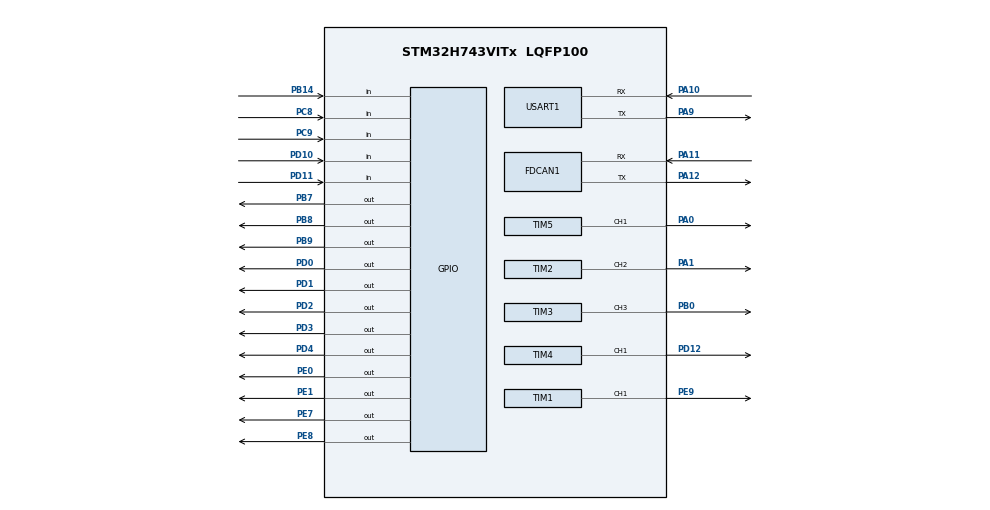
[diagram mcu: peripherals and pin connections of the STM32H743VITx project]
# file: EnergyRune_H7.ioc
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CORTEX_M7.AccessPermission_S-Cortex_Memory_Protection_Unit_Region1_Settings_S=MPU_REGION_FULL_ACCESS
CORTEX_M7.BaseAddress_S-Cortex_Memory_Protection_Unit_Region1_Settings_S=0x30000000
CORTEX_M7.CPU_ICache=Enabled
CORTEX_M7.Enable_S-Cortex_Memory_Protection_Unit_Region1_Settings_S=MPU_REGION_ENABLE
CORTEX_M7.IsBufferable_S-Cortex_Memory_Protection_Unit_Region1_Settings_S=MPU_ACCESS_BUFFERABLE
CORTEX_M7.IsShareable_S-Cortex_Memory_Protection_Unit_Region1_Settings_S=MPU_ACCESS_SHAREABLE
CORTEX_M7.Size_S-Cortex_Memory_Protection_Unit_Region1_Settings_S=MPU_REGION_SIZE_256KB
CORTEX_M7.TypeExtField_S-Cortex_Memory_Protection_Unit_Region1_Settings_S=MPU_TEX_LEVEL1
CORTEX_M7.default_mode_Activation=1
Dma.Request0=TIM4_CH1
Dma.Request1=TIM3_CH3
Dma.TIM3_CH3.1.Direction=DMA_MEMORY_TO_PERIPH
Dma.TIM3_CH3.1.EventEnable=DISABLE
Dma.TIM3_CH3.1.FIFOMode=DMA_FIFOMODE_DISABLE
Dma.TIM3_CH3.1.Instance=DMA1_Stream3
Dma.TIM3_CH3.1.MemDataAlignment=DMA_MDATAALIGN_HALFWORD
Dma.TIM3_CH3.1.MemInc=DMA_MINC_ENABLE
Dma.TIM3_CH3.1.Mode=DMA_NORMAL
Dma.TIM3_CH3.1.PeriphDataAlignment=DMA_PDATAALIGN_HALFWORD
Dma.TIM3_CH3.1.PeriphInc=DMA_PINC_DISABLE
Dma.TIM3_CH3.1.Polarity=HAL_DMAMUX_REQ_GEN_RISING
Dma.TIM3_CH3.1.Priority=DMA_PRIORITY_HIGH
Dma.TIM3_CH3.1.RequestNumber=1
Dma.TIM3_CH3.1.SignalID=NONE
Dma.TIM3_CH3.1.SyncEnable=DISABLE
Dma.TIM3_CH3.1.SyncPolarity=HAL_DMAMUX_SYNC_NO_EVENT
Dma.TIM3_CH3.1.SyncRequestNumber=1
Dma.TIM3_CH3.1.SyncSignalID=NONE
Dma.TIM4_CH1.0.Direction=DMA_MEMORY_TO_PERIPH
Dma.TIM4_CH1.0.EventEnable=DISABLE
Dma.TIM4_CH1.0.FIFOMode=DMA_FIFOMODE_DISABLE
Dma.TIM4_CH1.0.Instance=DMA1_Stream0
Dma.TIM4_CH1.0.MemDataAlignment=DMA_MDATAALIGN_HALFWORD
Dma.TIM4_CH1.0.MemInc=DMA_MINC_ENABLE
Dma.TIM4_CH1.0.Mode=DMA_NORMAL
Dma.TIM4_CH1.0.PeriphDataAlignment=DMA_PDATAALIGN_HALFWORD
Dma.TIM4_CH1.0.PeriphInc=DMA_PINC_DISABLE
Dma.TIM4_CH1.0.Polarity=HAL_DMAMUX_REQ_GEN_RISING
Dma.TIM4_CH1.0.Priority=DMA_PRIORITY_HIGH
Dma.TIM4_CH1.0.RequestNumber=1
Dma.TIM4_CH1.0.SignalID=NONE
Dma.TIM4_CH1.0.SyncEnable=DISABLE
Dma.TIM4_CH1.0.SyncPolarity=HAL_DMAMUX_SYNC_NO_EVENT
Dma.TIM4_CH1.0.SyncRequestNumber=1
Dma.TIM4_CH1.0.SyncSignalID=NONE
FDCAN1.CalculateBaudRateNominal=1000000
FDCAN1.CalculateTimeBitNominal=1000
FDCAN1.CalculateTimeQuantumNominal=50.0
FDCAN1.NominalPrescaler=6
FDCAN1.NominalTimeSeg1=15
FDCAN1.NominalTimeSeg2=4
FDCAN1.RxFifo0ElmtsNbr=32
FDCAN1.StdFiltersNbr=1
Mcu.Family=STM32H7
Mcu.Name=STM32H743VITx
Mcu.Package=LQFP100
NVIC.DMA1_Stream0_IRQn=true\:0\:0\:false\:false\:true\:false\:true\:true
NVIC.DMA1_Stream3_IRQn=true\:0\:0\:false\:false\:true\:false\:true\:true
NVIC.PriorityGroup=NVIC_PRIORITYGROUP_4
NVIC.TIM3_IRQn=true\:0\:0\:false\:false\:true\:true\:true\:true
NVIC.TIM4_IRQn=true\:0\:0\:false\:false\:true\:true\:true\:true
NVIC.TIM6_DAC_IRQn=true\:0\:0\:false\:false\:true\:true\:true\:true
PA0.Signal=S_TIM5_CH1
PA1.Signal=S_TIM2_CH2
PA10.Mode=Asynchronous
PA10.Signal=USART1_RX
PA11.Mode=FDCAN_Activate
PA11.Signal=FDCAN1_RX
PA12.Mode=FDCAN_Activate
PA12.Signal=FDCAN1_TX
PA13\ (JTMS/SWDIO).Mode=Serial_Wire
PA13\ (JTMS/SWDIO).Signal=DEBUG_JTMS-SWDIO
PA14\ (JTCK/SWCLK).Mode=Serial_Wire
PA14\ (JTCK/SWCLK).Signal=DEBUG_JTCK-SWCLK
PA9.Mode=Asynchronous
PA9.Signal=USART1_TX
PB0.Signal=S_TIM3_CH3
PB14.Signal=GPIO_Input
PB7.Signal=GPIO_Output
PB8.Signal=GPIO_Output
PB9.Signal=GPIO_Output
PC8.Signal=GPIO_Input
PC9.Signal=GPIO_Input
PD0.Signal=GPIO_Output
PD1.Signal=GPIO_Output
PD10.Signal=GPIO_Input
PD11.Signal=GPIO_Input
PD12.Signal=S_TIM4_CH1
PD2.Signal=GPIO_Output
PD3.Signal=GPIO_Output
PD4.Signal=GPIO_Output
PE0.Signal=GPIO_Output
PE1.Signal=GPIO_Output
PE7.Signal=GPIO_Output
PE8.Signal=GPIO_Output
PE9.Signal=S_TIM1_CH1
PH0-OSC_IN\ (PH0).Mode=HSE-External-Oscillator
PH0-OSC_IN\ (PH0).Signal=RCC_OSC_IN
PH1-OSC_OUT\ (PH1).Mode=HSE-External-Oscillator
PH1-OSC_OUT\ (PH1).Signal=RCC_OSC_OUT
ProjectManager.HeapSize=0x200
ProjectManager.StackSize=0x400
ProjectManager.TargetToolchain=MDK-ARM V5.27
RCC.ADCFreq_Value=32250000
RCC.APB1Freq_Value=120000000
RCC.APB2Freq_Value=120000000
RCC.APB3Freq_Value=120000000
RCC.APB4Freq_Value=120000000
RCC.CortexFreq_Value=480000000
RCC.D1PPRE=RCC_APB3_DIV2
RCC.D2PPRE1=RCC_APB1_DIV2
RCC.D2PPRE2=RCC_APB2_DIV2
RCC.D3PPRE=RCC_APB4_DIV2
RCC.DIVM1=1
RCC.DIVN1=60
RCC.DIVQ1=8
RCC.HCLKFreq_Value=240000000
RCC.HPRE=RCC_HCLK_DIV2
RCC.HSE_VALUE=16000000
RCC.PLLFRACN=0
RCC.PLLSourceVirtual=RCC_PLLSOURCE_HSE
RCC.SYSCLKFreq_VALUE=480000000
RCC.SYSCLKSource=RCC_SYSCLKSOURCE_PLLCLK
RCC.USBFreq_Value=120000000
SH.S_TIM1_CH1.0=TIM1_CH1,PWM Generation1 CH1
SH.S_TIM2_CH2.0=TIM2_CH2,PWM Generation2 CH2
SH.S_TIM3_CH3.0=TIM3_CH3,PWM Generation3 CH3
SH.S_TIM4_CH1.0=TIM4_CH1,PWM Generation1 CH1
SH.S_TIM5_CH1.0=TIM5_CH1,PWM Generation1 CH1
TIM1.Channel-PWM\ Generation1\ CH1=TIM_CHANNEL_1
TIM1.Period=299
TIM2.Channel-PWM\ Generation2\ CH2=TIM_CHANNEL_2
TIM2.Period=299
TIM3.Channel-PWM\ Generation3\ CH3=TIM_CHANNEL_3
TIM3.Period=299
TIM4.Channel-PWM\ Generation1\ CH1=TIM_CHANNEL_1
TIM4.CounterMode=TIM_COUNTERMODE_UP
TIM4.Period=299
TIM5.Channel-PWM\ Generation1\ CH1=TIM_CHANNEL_1
TIM5.Period=299
TIM6.Period=9999
TIM6.Prescaler=24
USART1.VirtualMode-Asynchronous=VM_ASYNC
VP_MEMORYMAP_VS_MEMORYMAP.Mode=CurAppReg
VP_RNG_VS_RNG.Mode=RNG_Activate
VP_TIM3_VS_ClockSourceINT.Mode=Internal
VP_TIM4_VS_ClockSourceINT.Mode=Internal
VP_TIM6_VS_ClockSourceINT.Mode=Enable_Timer
board=custom

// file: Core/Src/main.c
/* USER CODE BEGIN Header */
/**
  ******************************************************************************
  * @file           : main.c
  * @brief          : Main program body
  ******************************************************************************
  * @attention
  *
  * Copyright (c) 2026 STMicroelectronics.
  * All rights reserved.
  *
  * This software is licensed under terms that can be found in the LICENSE file
  * in the root directory of this software component.
  * If no LICENSE file comes with this software, it is provided AS-IS.
  *
  ******************************************************************************
  */
/* USER CODE END Header */
#include "main.h"

#include "cmd_parser.h"
#include "software_config.h"

FDCAN_HandleTypeDef hfdcan1;

RNG_HandleTypeDef hrng;

TIM_HandleTypeDef htim1;
TIM_HandleTypeDef htim2;
TIM_HandleTypeDef htim3;
TIM_HandleTypeDef htim4;
TIM_HandleTypeDef htim5;
TIM_HandleTypeDef htim6;
DMA_HandleTypeDef hdma_tim3_ch3;
DMA_HandleTypeDef hdma_tim4_ch1;

UART_HandleTypeDef huart1;

/* USER CODE BEGIN PV */
int rune_mode  = BIG_RUNE;
gError_t gError=
    {
    0,0,0
};
extern int flag_data_process;
/* USER CODE END PV */

void SystemClock_Config(void);
static void MPU_Config(void);
static void MX_GPIO_Init(void);
static void MX_DMA_Init(void);
static void MX_FDCAN1_Init(void);
static void MX_TIM3_Init(void);
static void MX_TIM4_Init(void);
static void MX_TIM6_Init(void);
static void MX_USART1_UART_Init(void);
static void MX_RNG_Init(void);
static void MX_TIM1_Init(void);
static void MX_TIM2_Init(void);
static void MX_TIM5_Init(void);

int main(void)
{

  /* USER CODE BEGIN 1 */
int ok=0;
  /* USER CODE END 1 */

  /* MPU Configuration--------------------------------------------------------*/
  MPU_Config();

  /* Enable the CPU Cache */

  /* Enable I-Cache---------------------------------------------------------*/
  SCB_EnableICache();

  /* MCU Configuration--------------------------------------------------------*/

  /* Reset of all peripherals, Initializes the Flash interface and the Systick. */
  HAL_Init();

  /* Configure the system clock */
  SystemClock_Config();

  /* Initialize all configured peripherals */
  MX_GPIO_Init();
  MX_DMA_Init();
  MX_FDCAN1_Init();
  MX_TIM3_Init();
  MX_TIM4_Init();
  MX_TIM6_Init();
  MX_USART1_UART_Init();
  MX_RNG_Init();
  MX_TIM1_Init();
  MX_TIM2_Init();
  MX_TIM5_Init();
  /* USER CODE BEGIN 2 */
    HAL_TIM_Base_Start_IT(&htim6);
  /* USER CODE END 2 */

  /* Infinite loop */
  while (1)
  {
    /* USER CODE BEGIN 3 */
if (flag_data_process=1)
    CmdParser_HandleUartData();
  }
  /* USER CODE END 3 */
}

void SystemClock_Config(void)
{
  RCC_OscInitTypeDef RCC_OscInitStruct = {0};
  RCC_ClkInitTypeDef RCC_ClkInitStruct = {0};

  /** Supply configuration update enable
  */
  HAL_PWREx_ConfigSupply(PWR_LDO_SUPPLY);

  /** Configure the main internal regulator output voltage
  */
  __HAL_PWR_VOLTAGESCALING_CONFIG(PWR_REGULATOR_VOLTAGE_SCALE0);

  while(!__HAL_PWR_GET_FLAG(PWR_FLAG_VOSRDY)) {}

  /** Initializes the RCC Oscillators according to the specified parameters
  * in the RCC_OscInitTypeDef structure.
  */
  RCC_OscInitStruct.OscillatorType = RCC_OSCILLATORTYPE_HSI48|RCC_OSCILLATORTYPE_HSE;
  RCC_OscInitStruct.HSEState = RCC_HSE_ON;
  RCC_OscInitStruct.HSI48State = RCC_HSI48_ON;
  RCC_OscInitStruct.PLL.PLLState = RCC_PLL_ON;
  RCC_OscInitStruct.PLL.PLLSource = RCC_PLLSOURCE_HSE;
  RCC_OscInitStruct.PLL.PLLM = 1;
  RCC_OscInitStruct.PLL.PLLN = 60;
  RCC_OscInitStruct.PLL.PLLP = 2;
  RCC_OscInitStruct.PLL.PLLQ = 8;
  RCC_OscInitStruct.PLL.PLLR = 2;
  RCC_OscInitStruct.PLL.PLLRGE = RCC_PLL1VCIRANGE_3;
  RCC_OscInitStruct.PLL.PLLVCOSEL = RCC_PLL1VCOWIDE;
  RCC_OscInitStruct.PLL.PLLFRACN = 0;
  if (HAL_RCC_OscConfig(&RCC_OscInitStruct) != HAL_OK)
  {
    Error_Handler();
  }

  /** Initializes the CPU, AHB and APB buses clocks
  */
  RCC_ClkInitStruct.ClockType = RCC_CLOCKTYPE_HCLK|RCC_CLOCKTYPE_SYSCLK
                              |RCC_CLOCKTYPE_PCLK1|RCC_CLOCKTYPE_PCLK2
                              |RCC_CLOCKTYPE_D3PCLK1|RCC_CLOCKTYPE_D1PCLK1;
  RCC_ClkInitStruct.SYSCLKSource = RCC_SYSCLKSOURCE_PLLCLK;
  RCC_ClkInitStruct.SYSCLKDivider = RCC_SYSCLK_DIV1;
  RCC_ClkInitStruct.AHBCLKDivider = RCC_HCLK_DIV2;
  RCC_ClkInitStruct.APB3CLKDivider = RCC_APB3_DIV2;
  RCC_ClkInitStruct.APB1CLKDivider = RCC_APB1_DIV2;
  RCC_ClkInitStruct.APB2CLKDivider = RCC_APB2_DIV2;
  RCC_ClkInitStruct.APB4CLKDivider = RCC_APB4_DIV2;

  if (HAL_RCC_ClockConfig(&RCC_ClkInitStruct, FLASH_LATENCY_4) != HAL_OK)
  {
    Error_Handler();
  }
}

static void MX_FDCAN1_Init(void)
{

  hfdcan1.Instance = FDCAN1;
  hfdcan1.Init.FrameFormat = FDCAN_FRAME_CLASSIC;
  hfdcan1.Init.Mode = FDCAN_MODE_NORMAL;
  hfdcan1.Init.AutoRetransmission = DISABLE;
  hfdcan1.Init.TransmitPause = DISABLE;
  hfdcan1.Init.ProtocolException = DISABLE;
  hfdcan1.Init.NominalPrescaler = 6;
  hfdcan1.Init.NominalSyncJumpWidth = 1;
  hfdcan1.Init.NominalTimeSeg1 = 15;
  hfdcan1.Init.NominalTimeSeg2 = 4;
  hfdcan1.Init.DataPrescaler = 1;
  hfdcan1.Init.DataSyncJumpWidth = 1;
  hfdcan1.Init.DataTimeSeg1 = 1;
  hfdcan1.Init.DataTimeSeg2 = 1;
  hfdcan1.Init.MessageRAMOffset = 0;
  hfdcan1.Init.StdFiltersNbr = 1;
  hfdcan1.Init.ExtFiltersNbr = 0;
  hfdcan1.Init.RxFifo0ElmtsNbr = 32;
  hfdcan1.Init.RxFifo0ElmtSize = FDCAN_DATA_BYTES_8;
  hfdcan1.Init.RxFifo1ElmtsNbr = 0;
  hfdcan1.Init.RxFifo1ElmtSize = FDCAN_DATA_BYTES_8;
  hfdcan1.Init.RxBuffersNbr = 0;
  hfdcan1.Init.RxBufferSize = FDCAN_DATA_BYTES_8;
  hfdcan1.Init.TxEventsNbr = 0;
  hfdcan1.Init.TxBuffersNbr = 0;
  hfdcan1.Init.TxFifoQueueElmtsNbr = 0;
  hfdcan1.Init.TxFifoQueueMode = FDCAN_TX_FIFO_OPERATION;
  hfdcan1.Init.TxElmtSize = FDCAN_DATA_BYTES_8;
  if (HAL_FDCAN_Init(&hfdcan1) != HAL_OK)
  {
    Error_Handler();
  }

}

static void MX_RNG_Init(void)
{

  hrng.Instance = RNG;
  hrng.Init.ClockErrorDetection = RNG_CED_ENABLE;
  if (HAL_RNG_Init(&hrng) != HAL_OK)
  {
    Error_Handler();
  }

}

static void MX_TIM1_Init(void)
{

  TIM_MasterConfigTypeDef sMasterConfig = {0};
  TIM_OC_InitTypeDef sConfigOC = {0};
  TIM_BreakDeadTimeConfigTypeDef sBreakDeadTimeConfig = {0};

  htim1.Instance = TIM1;
  htim1.Init.Prescaler = 0;
  htim1.Init.CounterMode = TIM_COUNTERMODE_UP;
  htim1.Init.Period = 299;
  htim1.Init.ClockDivision = TIM_CLOCKDIVISION_DIV1;
  htim1.Init.RepetitionCounter = 0;
  htim1.Init.AutoReloadPreload = TIM_AUTORELOAD_PRELOAD_DISABLE;
  if (HAL_TIM_PWM_Init(&htim1) != HAL_OK)
  {
    Error_Handler();
  }
  sMasterConfig.MasterOutputTrigger = TIM_TRGO_RESET;
  sMasterConfig.MasterOutputTrigger2 = TIM_TRGO2_RESET;
  sMasterConfig.MasterSlaveMode = TIM_MASTERSLAVEMODE_DISABLE;
  if (HAL_TIMEx_MasterConfigSynchronization(&htim1, &sMasterConfig) != HAL_OK)
  {
    Error_Handler();
  }
  sConfigOC.OCMode = TIM_OCMODE_PWM1;
  sConfigOC.Pulse = 0;
  sConfigOC.OCPolarity = TIM_OCPOLARITY_HIGH;
  sConfigOC.OCNPolarity = TIM_OCNPOLARITY_HIGH;
  sConfigOC.OCFastMode = TIM_OCFAST_DISABLE;
  sConfigOC.OCIdleState = TIM_OCIDLESTATE_RESET;
  sConfigOC.OCNIdleState = TIM_OCNIDLESTATE_RESET;
  if (HAL_TIM_PWM_ConfigChannel(&htim1, &sConfigOC, TIM_CHANNEL_1) != HAL_OK)
  {
    Error_Handler();
  }
  sBreakDeadTimeConfig.OffStateRunMode = TIM_OSSR_DISABLE;
  sBreakDeadTimeConfig.OffStateIDLEMode = TIM_OSSI_DISABLE;
  sBreakDeadTimeConfig.LockLevel = TIM_LOCKLEVEL_OFF;
  sBreakDeadTimeConfig.DeadTime = 0;
  sBreakDeadTimeConfig.BreakState = TIM_BREAK_DISABLE;
  sBreakDeadTimeConfig.BreakPolarity = TIM_BREAKPOLARITY_HIGH;
  sBreakDeadTimeConfig.BreakFilter = 0;
  sBreakDeadTimeConfig.Break2State = TIM_BREAK2_DISABLE;
  sBreakDeadTimeConfig.Break2Polarity = TIM_BREAK2POLARITY_HIGH;
  sBreakDeadTimeConfig.Break2Filter = 0;
  sBreakDeadTimeConfig.AutomaticOutput = TIM_AUTOMATICOUTPUT_DISABLE;
  if (HAL_TIMEx_ConfigBreakDeadTime(&htim1, &sBreakDeadTimeConfig) != HAL_OK)
  {
    Error_Handler();
  }
  HAL_TIM_MspPostInit(&htim1);

}

static void MX_TIM2_Init(void)
{

  TIM_MasterConfigTypeDef sMasterConfig = {0};
  TIM_OC_InitTypeDef sConfigOC = {0};

  htim2.Instance = TIM2;
  htim2.Init.Prescaler = 0;
  htim2.Init.CounterMode = TIM_COUNTERMODE_UP;
  htim2.Init.Period = 299;
  htim2.Init.ClockDivision = TIM_CLOCKDIVISION_DIV1;
  htim2.Init.AutoReloadPreload = TIM_AUTORELOAD_PRELOAD_DISABLE;
  if (HAL_TIM_PWM_Init(&htim2) != HAL_OK)
  {
    Error_Handler();
  }
  sMasterConfig.MasterOutputTrigger = TIM_TRGO_RESET;
  sMasterConfig.MasterSlaveMode = TIM_MASTERSLAVEMODE_DISABLE;
  if (HAL_TIMEx_MasterConfigSynchronization(&htim2, &sMasterConfig) != HAL_OK)
  {
    Error_Handler();
  }
  sConfigOC.OCMode = TIM_OCMODE_PWM1;
  sConfigOC.Pulse = 0;
  sConfigOC.OCPolarity = TIM_OCPOLARITY_HIGH;
  sConfigOC.OCFastMode = TIM_OCFAST_DISABLE;
  if (HAL_TIM_PWM_ConfigChannel(&htim2, &sConfigOC, TIM_CHANNEL_2) != HAL_OK)
  {
    Error_Handler();
  }
  HAL_TIM_MspPostInit(&htim2);

}

static void MX_TIM3_Init(void)
{

  TIM_ClockConfigTypeDef sClockSourceConfig = {0};
  TIM_MasterConfigTypeDef sMasterConfig = {0};
  TIM_OC_InitTypeDef sConfigOC = {0};

  htim3.Instance = TIM3;
  htim3.Init.Prescaler = 0;
  htim3.Init.CounterMode = TIM_COUNTERMODE_UP;
  htim3.Init.Period = 299;
  htim3.Init.ClockDivision = TIM_CLOCKDIVISION_DIV1;
  htim3.Init.AutoReloadPreload = TIM_AUTORELOAD_PRELOAD_DISABLE;
  if (HAL_TIM_Base_Init(&htim3) != HAL_OK)
  {
    Error_Handler();
  }
  sClockSourceConfig.ClockSource = TIM_CLOCKSOURCE_INTERNAL;
  if (HAL_TIM_ConfigClockSource(&htim3, &sClockSourceConfig) != HAL_OK)
  {
    Error_Handler();
  }
  if (HAL_TIM_PWM_Init(&htim3) != HAL_OK)
  {
    Error_Handler();
  }
  sMasterConfig.MasterOutputTrigger = TIM_TRGO_RESET;
  sMasterConfig.MasterSlaveMode = TIM_MASTERSLAVEMODE_DISABLE;
  if (HAL_TIMEx_MasterConfigSynchronization(&htim3, &sMasterConfig) != HAL_OK)
  {
    Error_Handler();
  }
  sConfigOC.OCMode = TIM_OCMODE_PWM1;
  sConfigOC.Pulse = 0;
  sConfigOC.OCPolarity = TIM_OCPOLARITY_HIGH;
  sConfigOC.OCFastMode = TIM_OCFAST_DISABLE;
  if (HAL_TIM_PWM_ConfigChannel(&htim3, &sConfigOC, TIM_CHANNEL_3) != HAL_OK)
  {
    Error_Handler();
  }
  HAL_TIM_MspPostInit(&htim3);

}

static void MX_TIM4_Init(void)
{

  TIM_ClockConfigTypeDef sClockSourceConfig = {0};
  TIM_MasterConfigTypeDef sMasterConfig = {0};
  TIM_OC_InitTypeDef sConfigOC = {0};

  htim4.Instance = TIM4;
  htim4.Init.Prescaler = 0;
  htim4.Init.CounterMode = TIM_COUNTERMODE_UP;
  htim4.Init.Period = 299;
  htim4.Init.ClockDivision = TIM_CLOCKDIVISION_DIV1;
  htim4.Init.AutoReloadPreload = TIM_AUTORELOAD_PRELOAD_DISABLE;
  if (HAL_TIM_Base_Init(&htim4) != HAL_OK)
  {
    Error_Handler();
  }
  sClockSourceConfig.ClockSource = TIM_CLOCKSOURCE_INTERNAL;
  if (HAL_TIM_ConfigClockSource(&htim4, &sClockSourceConfig) != HAL_OK)
  {
    Error_Handler();
  }
  if (HAL_TIM_PWM_Init(&htim4) != HAL_OK)
  {
    Error_Handler();
  }
  sMasterConfig.MasterOutputTrigger = TIM_TRGO_RESET;
  sMasterConfig.MasterSlaveMode = TIM_MASTERSLAVEMODE_DISABLE;
  if (HAL_TIMEx_MasterConfigSynchronization(&htim4, &sMasterConfig) != HAL_OK)
  {
    Error_Handler();
  }
  sConfigOC.OCMode = TIM_OCMODE_PWM1;
  sConfigOC.Pulse = 0;
  sConfigOC.OCPolarity = TIM_OCPOLARITY_HIGH;
  sConfigOC.OCFastMode = TIM_OCFAST_DISABLE;
  if (HAL_TIM_PWM_ConfigChannel(&htim4, &sConfigOC, TIM_CHANNEL_1) != HAL_OK)
  {
    Error_Handler();
  }
  HAL_TIM_MspPostInit(&htim4);

}

static void MX_TIM5_Init(void)
{

  TIM_MasterConfigTypeDef sMasterConfig = {0};
  TIM_OC_InitTypeDef sConfigOC = {0};

  htim5.Instance = TIM5;
  htim5.Init.Prescaler = 0;
  htim5.Init.CounterMode = TIM_COUNTERMODE_UP;
  htim5.Init.Period = 299;
  htim5.Init.ClockDivision = TIM_CLOCKDIVISION_DIV1;
  htim5.Init.AutoReloadPreload = TIM_AUTORELOAD_PRELOAD_DISABLE;
  if (HAL_TIM_PWM_Init(&htim5) != HAL_OK)
  {
    Error_Handler();
  }
  sMasterConfig.MasterOutputTrigger = TIM_TRGO_RESET;
  sMasterConfig.MasterSlaveMode = TIM_MASTERSLAVEMODE_DISABLE;
  if (HAL_TIMEx_MasterConfigSynchronization(&htim5, &sMasterConfig) != HAL_OK)
  {
    Error_Handler();
  }
  sConfigOC.OCMode = TIM_OCMODE_PWM1;
  sConfigOC.Pulse = 0;
  sConfigOC.OCPolarity = TIM_OCPOLARITY_HIGH;
  sConfigOC.OCFastMode = TIM_OCFAST_DISABLE;
  if (HAL_TIM_PWM_ConfigChannel(&htim5, &sConfigOC, TIM_CHANNEL_1) != HAL_OK)
  {
    Error_Handler();
  }
  HAL_TIM_MspPostInit(&htim5);

}

static void MX_TIM6_Init(void)
{

  TIM_MasterConfigTypeDef sMasterConfig = {0};

  htim6.Instance = TIM6;
  htim6.Init.Prescaler = 24;
  htim6.Init.CounterMode = TIM_COUNTERMODE_UP;
  htim6.Init.Period = 9999;
  htim6.Init.AutoReloadPreload = TIM_AUTORELOAD_PRELOAD_DISABLE;
  if (HAL_TIM_Base_Init(&htim6) != HAL_OK)
  {
    Error_Handler();
  }
  sMasterConfig.MasterOutputTrigger = TIM_TRGO_RESET;
  sMasterConfig.MasterSlaveMode = TIM_MASTERSLAVEMODE_DISABLE;
  if (HAL_TIMEx_MasterConfigSynchronization(&htim6, &sMasterConfig) != HAL_OK)
  {
    Error_Handler();
  }

}

static void MX_USART1_UART_Init(void)
{

  huart1.Instance = USART1;
  huart1.Init.BaudRate = 115200;
  huart1.Init.WordLength = UART_WORDLENGTH_8B;
  huart1.Init.StopBits = UART_STOPBITS_1;
  huart1.Init.Parity = UART_PARITY_NONE;
  huart1.Init.Mode = UART_MODE_TX_RX;
  huart1.Init.HwFlowCtl = UART_HWCONTROL_NONE;
  huart1.Init.OverSampling = UART_OVERSAMPLING_16;
  huart1.Init.OneBitSampling = UART_ONE_BIT_SAMPLE_DISABLE;
  huart1.Init.ClockPrescaler = UART_PRESCALER_DIV1;
  huart1.AdvancedInit.AdvFeatureInit = UART_ADVFEATURE_NO_INIT;
  if (HAL_UART_Init(&huart1) != HAL_OK)
  {
    Error_Handler();
  }
  if (HAL_UARTEx_SetTxFifoThreshold(&huart1, UART_TXFIFO_THRESHOLD_1_8) != HAL_OK)
  {
    Error_Handler();
  }
  if (HAL_UARTEx_SetRxFifoThreshold(&huart1, UART_RXFIFO_THRESHOLD_1_8) != HAL_OK)
  {
    Error_Handler();
  }
  if (HAL_UARTEx_DisableFifoMode(&huart1) != HAL_OK)
  {
    Error_Handler();
  }

}

static void MX_DMA_Init(void)
{

  /* DMA controller clock enable */
  __HAL_RCC_DMA1_CLK_ENABLE();

  /* DMA interrupt init */
  /* DMA1_Stream0_IRQn interrupt configuration */
  HAL_NVIC_SetPriority(DMA1_Stream0_IRQn, 0, 0);
  HAL_NVIC_EnableIRQ(DMA1_Stream0_IRQn);
  /* DMA1_Stream3_IRQn interrupt configuration */
  HAL_NVIC_SetPriority(DMA1_Stream3_IRQn, 0, 0);
  HAL_NVIC_EnableIRQ(DMA1_Stream3_IRQn);

}

static void MX_GPIO_Init(void)
{
  GPIO_InitTypeDef GPIO_InitStruct = {0};

  /* GPIO Ports Clock Enable */
  __HAL_RCC_GPIOH_CLK_ENABLE();
  __HAL_RCC_GPIOA_CLK_ENABLE();
  __HAL_RCC_GPIOB_CLK_ENABLE();
  __HAL_RCC_GPIOE_CLK_ENABLE();
  __HAL_RCC_GPIOD_CLK_ENABLE();
  __HAL_RCC_GPIOC_CLK_ENABLE();

  /*Configure GPIO pin Output Level */
  HAL_GPIO_WritePin(GPIOE, GPIO_PIN_7|GPIO_PIN_8|GPIO_PIN_0|GPIO_PIN_1, GPIO_PIN_RESET);

  /*Configure GPIO pin Output Level */
  HAL_GPIO_WritePin(GPIOD, GPIO_PIN_0|GPIO_PIN_1|GPIO_PIN_2|GPIO_PIN_3
                          |GPIO_PIN_4, GPIO_PIN_RESET);

  /*Configure GPIO pin Output Level */
  HAL_GPIO_WritePin(GPIOB, GPIO_PIN_7|GPIO_PIN_8|GPIO_PIN_9, GPIO_PIN_RESET);

  /*Configure GPIO pins : PE7 PE8 PE0 PE1 */
  GPIO_InitStruct.Pin = GPIO_PIN_7|GPIO_PIN_8|GPIO_PIN_0|GPIO_PIN_1;
  GPIO_InitStruct.Mode = GPIO_MODE_OUTPUT_PP;
  GPIO_InitStruct.Pull = GPIO_NOPULL;
  GPIO_InitStruct.Speed = GPIO_SPEED_FREQ_LOW;
  HAL_GPIO_Init(GPIOE, &GPIO_InitStruct);

  /*Configure GPIO pin : PB14 */
  GPIO_InitStruct.Pin = GPIO_PIN_14;
  GPIO_InitStruct.Mode = GPIO_MODE_INPUT;
  GPIO_InitStruct.Pull = GPIO_NOPULL;
  HAL_GPIO_Init(GPIOB, &GPIO_InitStruct);

  /*Configure GPIO pins : PD10 PD11 */
  GPIO_InitStruct.Pin = GPIO_PIN_10|GPIO_PIN_11;
  GPIO_InitStruct.Mode = GPIO_MODE_INPUT;
  GPIO_InitStruct.Pull = GPIO_NOPULL;
  HAL_GPIO_Init(GPIOD, &GPIO_InitStruct);

  /*Configure GPIO pins : PC8 PC9 */
  GPIO_InitStruct.Pin = GPIO_PIN_8|GPIO_PIN_9;
  GPIO_InitStruct.Mode = GPIO_MODE_INPUT;
  GPIO_InitStruct.Pull = GPIO_NOPULL;
  HAL_GPIO_Init(GPIOC, &GPIO_InitStruct);

  /*Configure GPIO pins : PD0 PD1 PD2 PD3
                           PD4 */
  GPIO_InitStruct.Pin = GPIO_PIN_0|GPIO_PIN_1|GPIO_PIN_2|GPIO_PIN_3
                          |GPIO_PIN_4;
  GPIO_InitStruct.Mode = GPIO_MODE_OUTPUT_PP;
  GPIO_InitStruct.Pull = GPIO_NOPULL;
  GPIO_InitStruct.Speed = GPIO_SPEED_FREQ_LOW;
  HAL_GPIO_Init(GPIOD, &GPIO_InitStruct);

  /*Configure GPIO pins : PB7 PB8 PB9 */
  GPIO_InitStruct.Pin = GPIO_PIN_7|GPIO_PIN_8|GPIO_PIN_9;
  GPIO_InitStruct.Mode = GPIO_MODE_OUTPUT_PP;
  GPIO_InitStruct.Pull = GPIO_NOPULL;
  GPIO_InitStruct.Speed = GPIO_SPEED_FREQ_LOW;
  HAL_GPIO_Init(GPIOB, &GPIO_InitStruct);

}

 /* MPU Configuration */

void MPU_Config(void)
{
  MPU_Region_InitTypeDef MPU_InitStruct = {0};

  /* Disables the MPU */
  HAL_MPU_Disable();

  /** Initializes and configures the Region and the memory to be protected
  */
  MPU_InitStruct.Enable = MPU_REGION_ENABLE;
  MPU_InitStruct.Number = MPU_REGION_NUMBER0;
  MPU_InitStruct.BaseAddress = 0x0;
  MPU_InitStruct.Size = MPU_REGION_SIZE_4GB;
  MPU_InitStruct.SubRegionDisable = 0x87;
  MPU_InitStruct.TypeExtField = MPU_TEX_LEVEL0;
  MPU_InitStruct.AccessPermission = MPU_REGION_NO_ACCESS;
  MPU_InitStruct.DisableExec = MPU_INSTRUCTION_ACCESS_DISABLE;
  MPU_InitStruct.IsShareable = MPU_ACCESS_SHAREABLE;
  MPU_InitStruct.IsCacheable = MPU_ACCESS_NOT_CACHEABLE;
  MPU_InitStruct.IsBufferable = MPU_ACCESS_NOT_BUFFERABLE;

  HAL_MPU_ConfigRegion(&MPU_InitStruct);

  /** Initializes and configures the Region and the memory to be protected
  */
  MPU_InitStruct.Number = MPU_REGION_NUMBER1;
  MPU_InitStruct.BaseAddress = 0x30000000;
  MPU_InitStruct.Size = MPU_REGION_SIZE_256KB;
  MPU_InitStruct.SubRegionDisable = 0x0;
  MPU_InitStruct.TypeExtField = MPU_TEX_LEVEL1;
  MPU_InitStruct.AccessPermission = MPU_REGION_FULL_ACCESS;
  MPU_InitStruct.DisableExec = MPU_INSTRUCTION_ACCESS_ENABLE;
  MPU_InitStruct.IsBufferable = MPU_ACCESS_BUFFERABLE;

  HAL_MPU_ConfigRegion(&MPU_InitStruct);
  /* Enables the MPU */
  HAL_MPU_Enable(MPU_PRIVILEGED_DEFAULT);

}

void Error_Handler(void)
{
  __disable_irq();
  while (1)
  {
  }
}
